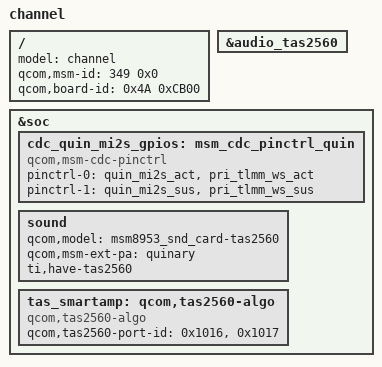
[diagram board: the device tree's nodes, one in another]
/* Copyright (c) 2018, The Linux Foundation. All rights reserved.
 *
 * This program is free software; you can redistribute it and/or modify
 * it under the terms of the GNU General Public License version 2 and
 * only version 2 as published by the Free Software Foundation.
 *
 * This program is distributed in the hope that it will be useful,
 * but WITHOUT ANY WARRANTY; without even the implied warranty of
 * MERCHANTABILITY or FITNESS FOR A PARTICULAR PURPOSE.  See the
 * GNU General Public License for more details.
 */

/dts-v1/;
/plugin/;

#include <dt-bindings/clock/msm-clocks-8953.h>

#include "sdm632-channel-common-overlay.dtsi"

/ {
	model = "channel";
	qcom,msm-id = <349 0x0>;
	qcom,board-id = <0x4A 0xCB00>;
};

/*
 * Channel RoW HW rev PVTB specific changes go here
 */

&audio_tas2560 {
        status = "ok";
};

&soc {
        cdc_quin_mi2s_gpios: msm_cdc_pinctrl_quin {
                compatible = "qcom,msm-cdc-pinctrl";
                pinctrl-names = "aud_active", "aud_sleep";
                pinctrl-0 = <&quin_mi2s_act &pri_tlmm_ws_act>;
                pinctrl-1 = <&quin_mi2s_sus &pri_tlmm_ws_sus>;
        };

        sound {
                qcom,model = "msm8953_snd_card-tas2560";
                qcom,msm-ext-pa = "quinary";
                ti,have-tas2560;
        };

        tas_smartamp: qcom,tas2560-algo {
                compatible = "qcom,tas2560-algo";
                qcom,tas2560-port-id = <0x1016>, <0x1017>; /*<RX_PORT_ID>, <TX_PORT_ID>*/
        };
};

